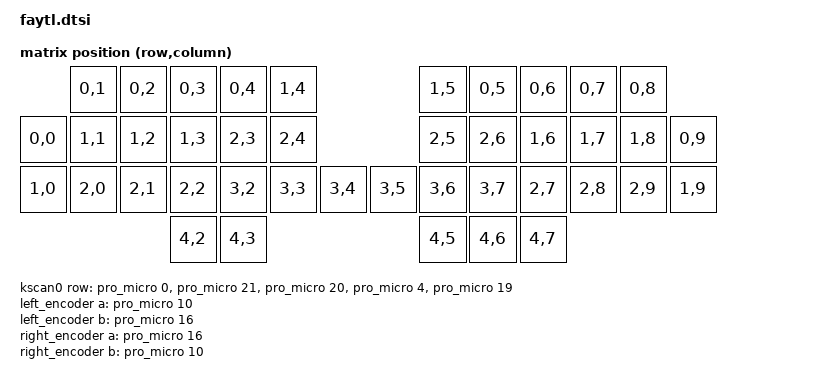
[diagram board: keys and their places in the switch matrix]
// This file was generated from a template. Edit it to match your keyboard.
// See https://zmk.dev/docs/development/hardware-integration/new-shield for more
// instructions.

#include <dt-bindings/zmk/matrix_transform.h>

#include "faytl-layouts.dtsi"

/ {
    chosen {
        zmk,physical-layout = &default_layout;
    };

    kscan0: kscan {
        compatible = "zmk,kscan-gpio-matrix";
        diode-direction = "col2row";
        wakeup-source;

        row-gpios
            = <&pro_micro 0 (GPIO_ACTIVE_HIGH | GPIO_PULL_DOWN)>
            , <&pro_micro 21 (GPIO_ACTIVE_HIGH | GPIO_PULL_DOWN)>
            , <&pro_micro 20 (GPIO_ACTIVE_HIGH | GPIO_PULL_DOWN)>
            , <&pro_micro 4 (GPIO_ACTIVE_HIGH | GPIO_PULL_DOWN)>
            , <&pro_micro 19 (GPIO_ACTIVE_HIGH | GPIO_PULL_DOWN)>
            ;
    };

    default_transform: default_transform {
        compatible = "zmk,matrix-transform";
        columns = <10>;
        rows = <5>;

        map = <
        // LEFT SIDE                                                     ENCODERS          RIGHT SIDE
        // outer  | pinky  |  ring  | middle | index  | inner  | |                     | |  inner |  index | middle |  ring  |  pinky |  outer
                    RC(0,1)  RC(0,2)  RC(0,3)  RC(0,4)  RC(1,4)                            RC(1,5)  RC(0,5)  RC(0,6)  RC(0,7)  RC(0,8)
           RC(0,0)  RC(1,1)  RC(1,2)  RC(1,3)  RC(2,3)  RC(2,4)                            RC(2,5)  RC(2,6)  RC(1,6)  RC(1,7)  RC(1,8)  RC(0,9)
           RC(1,0)  RC(2,0)  RC(2,1)  RC(2,2)  RC(3,2)  RC(3,3)     RC(3,4)   RC(3,5)      RC(3,6)  RC(3,7)  RC(2,7)  RC(2,8)  RC(2,9)  RC(1,9)
        //                                            THUMBS LEFT                      THUMBS RIGHT
        //                           | inner  | middle | outer  | |                    | |  outer | middle |  inner |
                                       RC(4,2)  RC(4,3)  RC (4,4)                         RC(4,5)  RC(4,6)  RC(4,7)
        >;
    };

    left_encoder: encoder_left {
        compatible = "alps,ec11";
        a-gpios = <&pro_micro 10 (GPIO_ACTIVE_HIGH | GPIO_PULL_UP)>;
        b-gpios = <&pro_micro 16 (GPIO_ACTIVE_HIGH | GPIO_PULL_UP)>;
        steps = <12>;
        status = "disabled";
    };

    right_encoder: encoder_right {
        compatible = "alps,ec11";
        a-gpios = <&pro_micro 16 (GPIO_ACTIVE_HIGH | GPIO_PULL_UP)>;
        b-gpios = <&pro_micro 10 (GPIO_ACTIVE_HIGH | GPIO_PULL_UP)>;
        steps = <12>;
        status = "disabled";
    };

    sensors: sensors {
        compatible = "zmk,keymap-sensors";
        sensors = <&left_encoder &right_encoder>;
        triggers-per-rotation = <12>;
    };
};
